# ATmega32U2 register map
Vendor: Atmel; File version: 1.0
CPU: other r0p0, little endian, no MPU, no FPU, 4 interrupt priority bits
Registers are 8-bit, read-write, reset 0x0 unless marked. A register's access mark holds for its fields unless they carry their own. Offsets are from the block's base; [hi:lo] are bit positions; {n}, {i} and the like mark numbered series; 'fields as' and 'values as' point back to an identical list.

## EEPROM
Base 0x0080003F
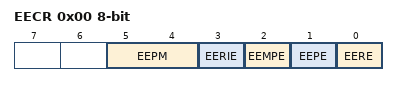
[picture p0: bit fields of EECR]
0x00 EECR — EEPROM Control Register
  [5:4] EEPM — EEPROM Programming Mode Bits
    0=ERASE_AND_WRITE_IN_ONE_OPERATION; 1=ERASE_ONLY; 2=WRITE_ONLY
  [3] EERIE — EEPROM Ready Interrupt Enable
  [2] EEMPE — EEPROM Master Write Enable
  [1] EEPE — EEPROM Write Enable
  [0] EERE — EEPROM Read Enable
0x01 EEDR — EEPROM Data Register
0x02 EEAR 16-bit (reset mask 0xFF) — EEPROM Address Register Low Bytes

## EXINT — External Interrupts
Base 0x0080003B
0x00 PCIFR — Pin Change Interrupt Flag Register (read-only for debugger)
  [1:0] PCIF — Pin Change Interrupt Flags
0x01 EIFR — External Interrupt Flag Register (read-only for debugger)
  [7:0] INTF — External Interrupt Flags
0x02 EIMSK — External Interrupt Mask Register
  [7:0] INT — External Interrupt Request 7 Enable
0x2D PCICR — Pin Change Interrupt Control Register
  [1:0] PCIE — Pin Change Interrupt Enables
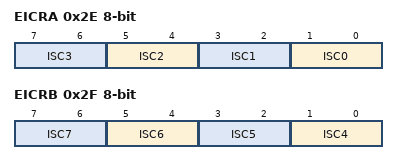
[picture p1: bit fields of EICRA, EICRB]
0x2E EICRA — External Interrupt Control Register A
  [2n+1:2n] ISC{n} (n=0..3) — External Interrupt Sense Control Bit
0x2F EICRB — External Interrupt Control Register B
  [2n-7:2n-8] ISC{n} (n=4..7) — External Interrupt 7-4 Sense Control Bit
0x30 PCMSK0 — Pin Change Mask Register 0
  [7:0] PCINT — Pin Change Enable Masks
0x31 PCMSK1 — Pin Change Mask Register 1
  [4:0] PCINT

## PLL — Phase Locked Loop
Base 0x00800049
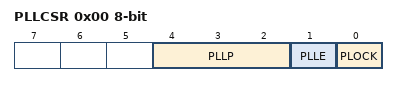
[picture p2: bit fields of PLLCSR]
0x00 PLLCSR — PLL Status and Control register
  [4:2] PLLP — PLL prescaler Bits
    3=CLOCK_4; 5=CLOCK_8
  [1] PLLE — PLL Enable Bit
  [0] PLOCK — PLL Lock Status Bit

## PORTB — I/O Port
Base 0x00800023
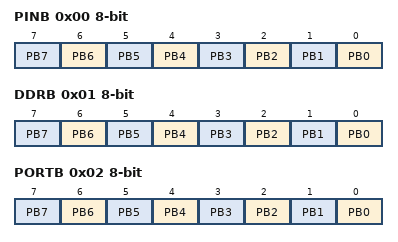
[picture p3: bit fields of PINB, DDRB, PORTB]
0x00 PINB — Port B Input Pins (read-only for debugger)
  [n] PB{n} (n=0..7) — Pin B{n}
0x01 DDRB — Port B Data Direction Register
  [n] PB{n} (n=0..7) — Pin B{n}
0x02 PORTB — Port B Data Register
  [n] PB{n} (n=0..7) — Pin B{n}

## PORTC — I/O Port
Base 0x00800026
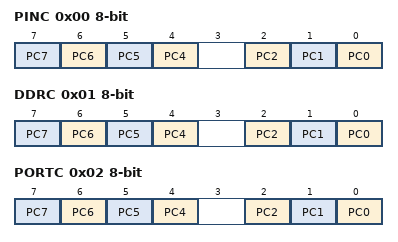
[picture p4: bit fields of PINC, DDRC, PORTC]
0x00 PINC — Port C Input Pins (read-only for debugger)
  [n] PC{n} (n=4..7) — Pin C{n}
  [2] PC2 — Pin C2
  [1] PC1 — Pin C1
  [0] PC0 — Pin C0
0x01 DDRC — Port C Data Direction Register
  fields as PINC
0x02 PORTC — Port C Data Register
  fields as PINC

## PORTD — I/O Port
Base 0x00800029
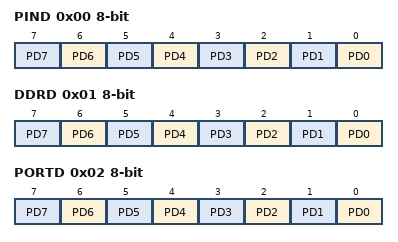
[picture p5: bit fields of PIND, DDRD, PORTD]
0x00 PIND — Port D Input Pins (read-only for debugger)
  [n] PD{n} (n=0..7) — Pin D{n}
0x01 DDRD — Port D Data Direction Register
  [n] PD{n} (n=0..7) — Pin D{n}
0x02 PORTD — Port D Data Register
  [n] PD{n} (n=0..7) — Pin D{n}

## SPI — Serial Peripheral Interface
Base 0x0080004C
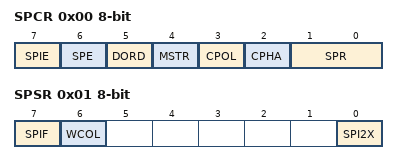
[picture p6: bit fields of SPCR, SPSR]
0x00 SPCR — SPI Control Register
  [7] SPIE — SPI Interrupt Enable
  [6] SPE — SPI Enable
  [5] DORD — Data Order
  [4] MSTR — Master/Slave Select
  [3] CPOL — Clock polarity
  [2] CPHA — Clock Phase
  [1:0] SPR — SPI Clock Rate Selects
    0=FOSC_4; 1=FOSC_16; 3=FOSC_128
0x01 SPSR — SPI Status Register (read-only for debugger)
  [7] SPIF — SPI Interrupt Flag
  [6] WCOL — Write Collision Flag
  [0] SPI2X — Double SPI Speed Bit
0x02 SPDR — SPI Data Register (write-only for debugger)

## TC0 — Timer/Counter, 8-bit
Base 0x00800035
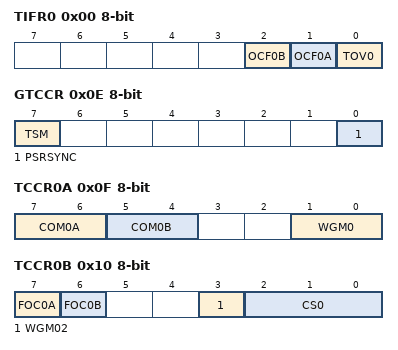
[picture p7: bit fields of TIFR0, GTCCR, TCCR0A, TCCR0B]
0x00 TIFR0 — Timer/Counter0 Interrupt Flag register (read-only for debugger)
  [2] OCF0B — Timer/Counter0 Output Compare Flag 0B
  [1] OCF0A — Timer/Counter0 Output Compare Flag 0A
  [0] TOV0 — Timer/Counter0 Overflow Flag
0x0E GTCCR — General Timer/Counter Control Register
  [7] TSM — Timer/Counter Synchronization Mode
  [0] PSRSYNC — Prescaler Reset Timer/Counter1 and Timer/Counter0
0x0F TCCR0A — Timer/Counter Control Register A
  [7:6] COM0A — Compare Output Mode, Phase Correct PWM Mode
  [5:4] COM0B — Compare Output Mode, Fast PWm
  [1:0] WGM0 — Waveform Generation Mode
0x10 TCCR0B — Timer/Counter Control Register B
  [7] FOC0A — Force Output Compare A
  [6] FOC0B — Force Output Compare B
  [3] WGM02
  [2:0] CS0 — Clock Select
    0=NO_CLOCK_SOURCE_STOPPED; 1=RUNNING_NO_PRESCALING; 2=RUNNING_CLK_8; 3=RUNNING_CLK_64; 4=RUNNING_CLK_256; 5=RUNNING_CLK_1024; 6=RUNNING_EXTCLK_TN_FALLING_EDGE; 7=RUNNING_EXTCLK_TN_RISING_EDGE
0x11 TCNT0 — Timer/Counter0
0x12 OCR0A — Timer/Counter0 Output Compare Register
0x13 OCR0B — Timer/Counter0 Output Compare Register
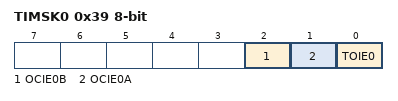
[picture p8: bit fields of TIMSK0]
0x39 TIMSK0 — Timer/Counter0 Interrupt Mask Register
  [2] OCIE0B — Timer/Counter0 Output Compare Match B Interrupt Enable
  [1] OCIE0A — Timer/Counter0 Output Compare Match A Interrupt Enable
  [0] TOIE0 — Timer/Counter0 Overflow Interrupt Enable

## TC1 — Timer/Counter, 16-bit
Base 0x00800036
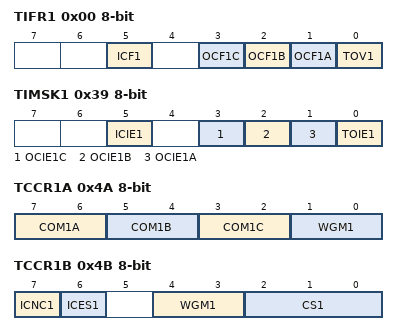
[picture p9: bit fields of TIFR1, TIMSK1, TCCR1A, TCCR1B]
0x00 TIFR1 — Timer/Counter1 Interrupt Flag register (read-only for debugger)
  [5] ICF1 — Input Capture Flag 1
  [3] OCF1C — Output Compare Flag 1C
  [2] OCF1B — Output Compare Flag 1B
  [1] OCF1A — Output Compare Flag 1A
  [0] TOV1 — Timer/Counter1 Overflow Flag
0x39 TIMSK1 — Timer/Counter1 Interrupt Mask Register
  [5] ICIE1 — Timer/Counter1 Input Capture Interrupt Enable
  [3] OCIE1C — Timer/Counter1 Output Compare C Match Interrupt Enable
  [2] OCIE1B — Timer/Counter1 Output Compare B Match Interrupt Enable
  [1] OCIE1A — Timer/Counter1 Output Compare A Match Interrupt Enable
  [0] TOIE1 — Timer/Counter1 Overflow Interrupt Enable
0x4A TCCR1A — Timer/Counter1 Control Register A
  [7:6] COM1A — Compare Output Mode 1A, bits
  [5:4] COM1B — Compare Output Mode 1B, bits
  [3:2] COM1C — Compare Output Mode 1C, bits
  [1:0] WGM1 — Waveform Generation Mode
0x4B TCCR1B — Timer/Counter1 Control Register B
  [7] ICNC1 — Input Capture 1 Noise Canceler
  [6] ICES1 — Input Capture 1 Edge Select
  [4:3] WGM1 — Waveform Generation Mode
  [2:0] CS1 — Prescaler source of Timer/Counter 1
    0=NO_CLOCK_SOURCE_STOPPED; 1=RUNNING_NO_PRESCALING; 2=RUNNING_CLK_8; 3=RUNNING_CLK_64; 4=RUNNING_CLK_256; 5=RUNNING_CLK_1024; 6=RUNNING_EXTCLK_TN_FALLING_EDGE; 7=RUNNING_EXTCLK_TN_RISING_EDGE
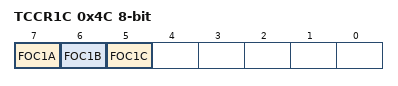
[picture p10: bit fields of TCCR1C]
0x4C TCCR1C — Timer/Counter 1 Control Register C
  [7] FOC1A — Force Output Compare 1A
  [6] FOC1B — Force Output Compare 1B
  [5] FOC1C — Force Output Compare 1C
0x4E TCNT1 16-bit (reset mask 0xFF) — Timer/Counter1 Bytes
0x50 ICR1 16-bit (reset mask 0xFF) — Timer/Counter1 Input Capture Register Bytes
0x52 OCR1A 16-bit (reset mask 0xFF) — Timer/Counter1 Output Compare Register A Bytes
0x54 OCR1B 16-bit (reset mask 0xFF) — Timer/Counter1 Output Compare Register B Bytes
0x56 OCR1C 16-bit (reset mask 0xFF) — Timer/Counter1 Output Compare Register C Bytes

## USART1 — USART
Base 0x008000C8
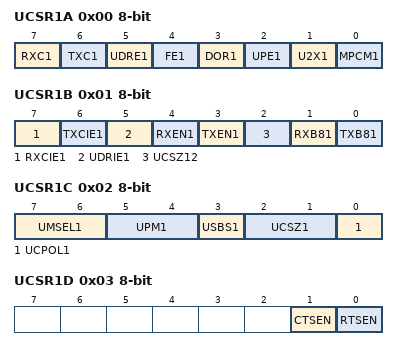
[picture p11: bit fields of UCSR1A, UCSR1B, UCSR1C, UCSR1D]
0x00 UCSR1A — USART Control and Status Register A
  [7] RXC1 — USART Receive Complete
  [6] TXC1 — USART Transmit Complete
  [5] UDRE1 — USART Data Register Empty
  [4] FE1 — Framing Error
  [3] DOR1 — Data overRun
  [2] UPE1 — Parity Error
  [1] U2X1 — Double the USART transmission speed
  [0] MPCM1 — Multi-processor Communication Mode
0x01 UCSR1B — USART Control and Status Register B
  [7] RXCIE1 — RX Complete Interrupt Enable
  [6] TXCIE1 — TX Complete Interrupt Enable
  [5] UDRIE1 — USART Data register Empty Interrupt Enable
  [4] RXEN1 — Receiver Enable
  [3] TXEN1 — Transmitter Enable
  [2] UCSZ12 — Character Size
  [1] RXB81 — Receive Data Bit 8
  [0] TXB81 — Transmit Data Bit 8
0x02 UCSR1C — USART Control and Status Register C
  [7:6] UMSEL1 — USART Mode Select
  [5:4] UPM1 — Parity Mode Bits
  [3] USBS1 — Stop Bit Select
  [2:1] UCSZ1 — Character Size
  [0] UCPOL1 — Clock Polarity
0x03 UCSR1D — USART Control and Status Register D
  [1] CTSEN — CTS Enable
  [0] RTSEN — RTS Enable
0x04 UBRR1 16-bit (reset mask 0xFF) — USART Baud Rate Register Bytes
0x06 UDR1 — USART I/O Data Register

## WDT — Watchdog Timer
Base 0x00800060
0x00 WDTCSR — Watchdog Timer Control Register (read-only for debugger)
  [7] WDIF — Watchdog Timeout Interrupt Flag
  [6] WDIE — Watchdog Timeout Interrupt Enable
  [4] WDCE — Watchdog Change Enable
  [3] WDE — Watch Dog Enable
  [5:0] WDP — Watchdog Timer Prescaler Bits
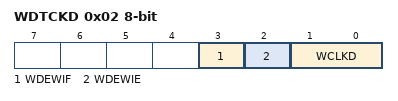
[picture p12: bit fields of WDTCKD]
0x02 WDTCKD — Watchdog Timer Clock Divider
  [3] WDEWIF — Watchdog Early Warning Interrupt Flag
  [2] WDEWIE — Watchdog Early Warning Interrupt Enable
  [1:0] WCLKD — Watchdog Timer Clock Dividers
